# R40 register map
Vendor: Allwinner; Series: R40; File version: 0.1
CPU: CA7 0, little endian, MPU, FPU, double-precision FPU, 0 interrupt priority bits
Registers are 32-bit, read-write, reset 0x0 unless marked. A register's access mark holds for its fields unless they carry their own. Offsets are from the block's base; [hi:lo] are bit positions; {n}, {i} and the like mark numbered series; 'fields as' and 'values as' point back to an identical list.

## RTP
Base 0x01C25000
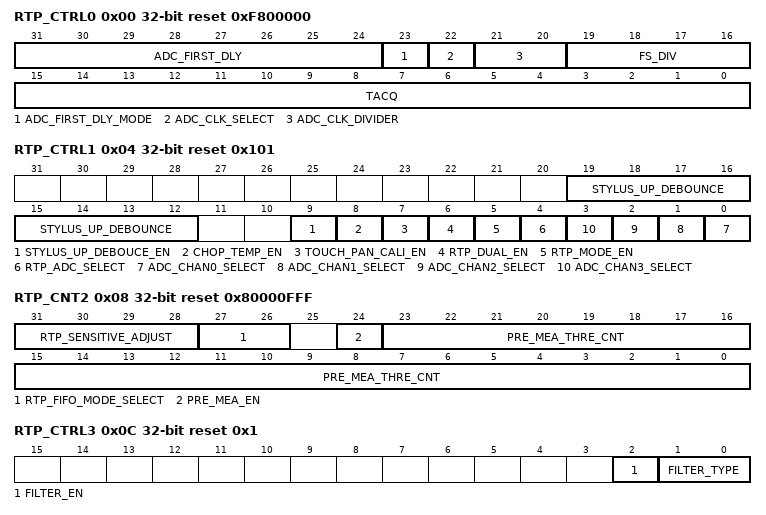
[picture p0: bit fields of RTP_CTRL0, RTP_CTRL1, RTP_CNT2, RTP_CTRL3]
0x00 RTP_CTRL0 reset 0xF800000 — RTP Control Register0
  [31:24] ADC_FIRST_DLY — ADC First Convert Delay Time(T_FCDT)setting Based on ADC First Convert Delay Mode select (Bit 23) T_FCDT = *
  [23] ADC_FIRST_DLY_MODE — ADC First Convert Delay Mode Select 0: CLK_IN/16 1: CLK_IN/16*256
    0=CLK_IN_slash_16 (CLK_IN/16); 1=CLK_IN_slash_16_times_256 (CLK_IN/16*256)
  [22] ADC_CLK_SELECT — ADC Clock Source Select 0: HOSC(24MHz) 1: Audio PLL
    0=HOSC_openingparen_24MHz_closingparen_ (HOSC(24MHz)); 1=Audio PLL
  [21:20] ADC_CLK_DIVIDER — ADC Clock Divider(CLK_IN) 00: CLK/2 01: CLK/3 10: CLK/6 11: CLK/1
    0=CLK_slash_2 (CLK/2); 1=CLK_slash_3 (CLK/3); 2=CLK_slash_6 (CLK/6); 3=CLK_slash_1 (CLK/1)
  [19:16] FS_DIV — ADC Sample Frequency Divider 0000: CLK_IN/2 0001: CLK_IN/2 0010: CLK_IN/2 .... 1111: CLK_IN/32
  [15:0] TACQ — Touch panel ADC acquire time CLK_IN/(16*(N+1))
0x04 RTP_CTRL1 reset 0x101 — RTP Control Register1
  [19:12] STYLUS_UP_DEBOUNCE — Stylus up De-bounce Time Setting 0x00: 0 .... 0xff: 2N*(CLK_IN/16*256)
    0=0 .... 0xff: 2N*(CLK_IN/16*256)
  [9] STYLUS_UP_DEBOUCE_EN — Stylus up De-bounce Function Select 0: Disable 1: Enable
    0=Disable; 1=Enable
  [8] CHOP_TEMP_EN — Chop Temperature Calibration Enable 0: Disable 1: Enable
    0=Disable; 1=Enable
  [7] TOUCH_PAN_CALI_EN — Touch Panel Calibration 1: Start calibration, it is cleared to 0 after calibration
    1=Start calibration, it is cleared to 0 after calibration
  [6] RTP_DUAL_EN — Touch Panel Double Point Enable 0: Disable 1: Enable
    0=Disable; 1=Enable
  [5] RTP_MODE_EN — RTP Mode Function Enable 0: Disable 1: Enable
    0=Disable; 1=Enable
  [4] RTP_ADC_SELECT — Touch Panel and ADC Select 0: TP 1: ADC
    0=TP; 1=ADC
  [n] ADC_CHAN{n}_SELECT (n=0..3) — Analog Input Channel {n} Select 0: Disable 1: Enable
    0=Disable; 1=Enable
0x08 RTP_CNT2 reset 0x80000FFF
  [31:28] RTP_SENSITIVE_ADJUST — Internal Pull-up Resistor Control 0000: least sensitive ... 1111: most sensitive Note: Used to adjust sensitivity of pen down detection
    0=least sensitive ; 15=most sensitive Note: Used to adjust sensitivity of pen down detection
  [27:26] RTP_FIFO_MODE_SELECT — RTP FIFO Access Data Mode Select 00: FIFO store X1,Y1 data for single touch no pressure mode 01: FIFO store X1,Y1, X, Y data for dual touch no pressure mode 10: FIFO store X1,Y1, X2,Y2 data for dual touch no pressure mode 11: FIFO store X1,Y1, X2,Y2,Z1,Z2 data for dual touch and pressure mode Note: The ADC output data in single touch mode can store in FIFO with TP_FIFO_MODE_SELECT configured as 01,10,11. But the data X, Y is theoretically equal to X1,Y1 , and X2,Y2 is equal to 0.
    0=FIFO_store_X1_comma_Y1_data (FIFO store X1,Y1 data for single touch no pressure mode); 1=FIFO_store_X1_comma_Y1_comma__X (FIFO store X1,Y1, X, Y data for dual touch no pressure mode); 2=FIFO_store_X1_comma_Y1_comma__X2_comma_Y2_data (FIFO store X1,Y1, X2,Y2 data for dual touch no pressure mode); 3=FIFO_store_X1_comma_Y1_comma__X2_comma_Y2_comma_Z1_comma_Z2_data (FIFO store X1,Y1, X2,Y2,Z1,Z2 data for dual touch and pressure mode Note: The ADC output data in single touch mode can store in FIFO with TP_FIFO_MODE_SELECT configured as 01,10,11. But the data X, Y is theoretically equal to X1,Y1 , and X2,Y2 is equal to 0.)
  [24] PRE_MEA_EN — RTP Pressure Measurement Enable Control 0: Disable 1: Enable
    0=Disable; 1=Enable
  [23:0] PRE_MEA_THRE_CNT — RTP Pressure Measurement threshold Control 0x000000:least sensitive 0xFFFFFF: most sensitive Note: Used to adjust sensitivity of touch
    0xFFFFFF=most sensitive Note: Used to adjust sensitivity of touch
0x0C RTP_CTRL3 reset 0x1 — Median and Averaging Filter Controller Register
  [2] FILTER_EN — Filter Enable 0: Disable 1: Enable
    0=Disable; 1=Enable
  [1:0] FILTER_TYPE — Filter Type 00: 4/2 01: 5/3 10: 8/4 11: 16/8
    0=_4_slash_2 (4/2); 1=_5_slash_3 (5/3); 2=_8_slash_4 (8/4); 3=_16_slash_8 (16/8)
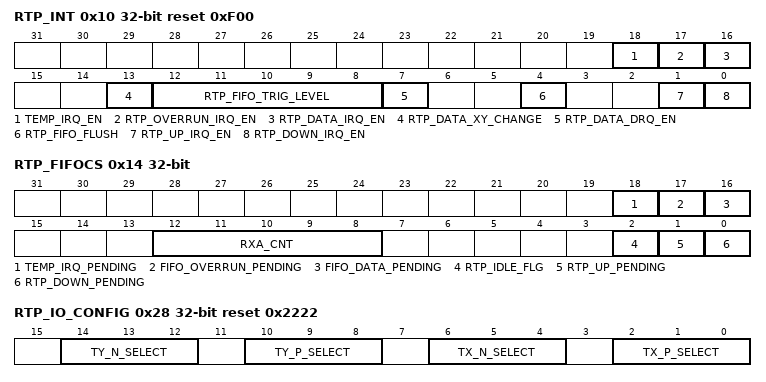
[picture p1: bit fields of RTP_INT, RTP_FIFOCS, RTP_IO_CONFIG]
0x10 RTP_INT reset 0xF00
  [18] TEMP_IRQ_EN — Temperature IRQ Enable 0: Disable 1: Enable
    0=Disable; 1=Enable
  [17] RTP_OVERRUN_IRQ_EN — RTP FIFO Over Run IRQ Enable 0: Disable 1: Enable
    0=Disable; 1=Enable
  [16] RTP_DATA_IRQ_EN — RTP FIFO Data Available IRQ Enable 0: Disable 1: Enable
    0=Disable; 1=Enable
  [13] RTP_DATA_XY_CHANGE — RTP FIFO X,Y Data interchange Function Select 0: Disable 1: Enable
    0=Disable; 1=Enable
  [12:8] RTP_FIFO_TRIG_LEVEL — RTP FIFO Data Available Trigger Level Interrupt and DMA request trigger level for TP or Auxiliary ADC Trigger Level = TXTL + 1
  [7] RTP_DATA_DRQ_EN — RTP FIFO Data Available DRQ Enable 0: Disable 1: Enable
    0=Disable; 1=Enable
  [4] RTP_FIFO_FLUSH — RTP FIFO Flush Write `1` to flush TX FIFO, self clear to `0`
  [1] RTP_UP_IRQ_EN — Touch Panel Last Touch (Stylus Up) IRQ Enable 0: Disable 1: Enable
    0=Disable; 1=Enable
  [0] RTP_DOWN_IRQ_EN — Touch Panel First Touch (Stylus Down) IRQ Enable 0: Disable 1: Enable
    0=Disable; 1=Enable
0x14 RTP_FIFOCS
  [18] TEMP_IRQ_PENDING write-1-clears — Temperature IRQ Pending 0: No Pending IRQ 1: FIFO Overrun Pending IRQ Write `1` to clear this interrupt or automatically clear if interrupt condition fails.
    0=No Pending IRQ; 1=FIFO (FIFO Overrun Pending IRQ Write `1` to clear this interrupt or automatically clear if interrupt condition fails.)
  [17] FIFO_OVERRUN_PENDING write-1-clears — RTP FIFO Over Run IRQ pending 0: No Pending IRQ 1: FIFO Overrun Pending IRQ Write `1` to clear this interrupt or automatically clear if interrupt condition fails.
    values as TEMP_IRQ_PENDING
  [16] FIFO_DATA_PENDING write-1-clears — RTP FIFO Data Available pending Bit 0: NO Pending IRQ 1: FIFO Available Pending IRQ Write `1` to clear this interrupt or automatically clear if interrupt condition fails.
    0=NO Pending IRQ; 1=FIFO (FIFO Available Pending IRQ Write `1` to clear this interrupt or automatically clear if interrupt condition fails.)
  [12:8] RXA_CNT ro — RTP FIFO available Sample Word Counter
  [2] RTP_IDLE_FLG ro — Touch Panel Idle Flag 0: idle 1: not idle
    0=idle; 1=not_idle
  [1] RTP_UP_PENDING write-1-clears — Touch Panel Last Touch (Stylus Up) IRQ Pending bit 0: No IRQ 1: IRQ Writing 1 to the bit will clear it and its corresponding interrupt if the interrupt is enabled.
    0=No_IRQ; 1=IRQ (IRQ Writing 1 to the bit will clear it and its corresponding interrupt if the interrupt is enabled.)
  [0] RTP_DOWN_PENDING write-1-clears — Touch Panel First Touch (Stylus Down) IRQ Pending bit 0: No IRQ 1: IRQ Writing 1 to the bit will clear it and its corresponding interrupt if the interrupt is enabled.
    values as RTP_UP_PENDING
0x1C RTP_CDAT reset 0x800 — RTP Common Data
  [11:0] TP_CDAT — TP Common Data Used to adjust the tolerance of the internal ADC
0x24 RTP_DATA
  [11:0] TP_DATA ro — Touch Panel X ,Ydata or Auxiliary analog input data converted by the internal ADC
0x28 RTP_IO_CONFIG reset 0x2222 — RTP IO Configuration
  [14:12] TY_N_SELECT — TY_N Port Function Select 000: Input 001:Output 010: TP_YN 011:/ 100: / 101:/ 110: / 111:/
    0=Input; 1=Output; 2=TP_YN
  [10:8] TY_P_SELECT — TY_P Port Function Select 000: Input 001:Output 010: TP_YP 011:/ 100: / 101:/ 110: / 111:/
    0=Input; 1=Output; 2=TP_YP
  [6:4] TX_N_SELECT — TX_P Port Function Select 000: Input 001:Output 010: TP_XN 011:/ 100: / 101:/ 110: / 111:/
    0=Input; 1=Output; 2=TP_XN
  [2:0] TX_P_SELECT — TX_P Port Function Select 000: Input 001:Output 010: TP_XP 011:/ 100: / 101:/ 110: / 111:/
    0=Input; 1=Output; 2=TP_XP
0x2C RTP_PORT_DATA — RTP IO Port Data
  [3:0] RTP_PORT_DATA — RTP Port Data Value, TP_YN,TP_YP, TP_XN, TP_XP(y2/y1/x2/x1)
